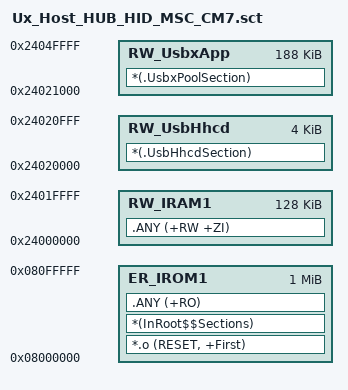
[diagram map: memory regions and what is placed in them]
; *************************************************************
; *** Scatter-Loading Description File generated by uVision ***
; *************************************************************

LR_IROM1 0x08000000 0x00100000  {    ; load region size_region
  ER_IROM1 0x08000000 0x00100000  {  ; load address = execution address
   *.o (RESET, +First)
   *(InRoot$$Sections)
   .ANY (+RO)
  }
  RW_IRAM1 0x24000000 0x20000 {
   .ANY (+RW +ZI)
  }
  RW_UsbHhcd 0x24020000 0x1000 {
   *(.UsbHhcdSection)
  }
  RW_UsbxApp 0x24021000 0x2F000 {
   *(.UsbxPoolSection)
  }
}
